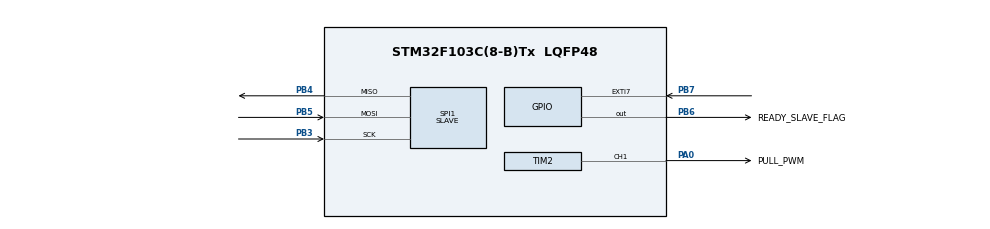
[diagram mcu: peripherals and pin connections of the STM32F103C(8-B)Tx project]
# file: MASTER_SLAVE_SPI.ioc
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Dma.Request0=SPI1_TX
Dma.Request1=SPI1_RX
Dma.SPI1_RX.1.Direction=DMA_PERIPH_TO_MEMORY
Dma.SPI1_RX.1.Instance=DMA1_Channel2
Dma.SPI1_RX.1.MemDataAlignment=DMA_MDATAALIGN_BYTE
Dma.SPI1_RX.1.MemInc=DMA_MINC_ENABLE
Dma.SPI1_RX.1.Mode=DMA_NORMAL
Dma.SPI1_RX.1.PeriphDataAlignment=DMA_PDATAALIGN_BYTE
Dma.SPI1_RX.1.PeriphInc=DMA_PINC_DISABLE
Dma.SPI1_RX.1.Priority=DMA_PRIORITY_LOW
Dma.SPI1_TX.0.Direction=DMA_MEMORY_TO_PERIPH
Dma.SPI1_TX.0.Instance=DMA1_Channel3
Dma.SPI1_TX.0.MemDataAlignment=DMA_MDATAALIGN_BYTE
Dma.SPI1_TX.0.MemInc=DMA_MINC_ENABLE
Dma.SPI1_TX.0.Mode=DMA_NORMAL
Dma.SPI1_TX.0.PeriphDataAlignment=DMA_PDATAALIGN_BYTE
Dma.SPI1_TX.0.PeriphInc=DMA_PINC_DISABLE
Dma.SPI1_TX.0.Priority=DMA_PRIORITY_LOW
Mcu.Family=STM32F1
Mcu.Name=STM32F103C(8-B)Tx
Mcu.Package=LQFP48
NVIC.DMA1_Channel2_IRQn=true\:0\:0\:false\:false\:true\:false\:true\:true
NVIC.DMA1_Channel3_IRQn=true\:0\:0\:false\:false\:true\:false\:true\:true
NVIC.EXTI9_5_IRQn=true\:0\:0\:false\:false\:true\:true\:true\:true
NVIC.PriorityGroup=NVIC_PRIORITYGROUP_4
NVIC.SPI1_IRQn=true\:0\:0\:false\:false\:true\:true\:true\:true
NVIC.TIM1_BRK_IRQn=true\:0\:0\:false\:false\:true\:true\:true\:true
NVIC.TIM1_UP_IRQn=true\:0\:0\:false\:false\:true\:true\:true\:true
PA0-WKUP.GPIO_Label=PULL_PWM
PA0-WKUP.GPIO_ModeDefaultPP=GPIO_MODE_AF_OD
PA0-WKUP.Signal=S_TIM2_CH1_ETR
PB3.Mode=Full_Duplex_Slave
PB3.Signal=SPI1_SCK
PB4.Mode=Full_Duplex_Slave
PB4.Signal=SPI1_MISO
PB5.Mode=Full_Duplex_Slave
PB5.Signal=SPI1_MOSI
PB6.GPIO_Label=READY_SLAVE_FLAG
PB6.Signal=GPIO_Output
PB7.GPIO_ModeDefaultEXTI=GPIO_MODE_IT_FALLING
PB7.Signal=GPXTI7
PD0-OSC_IN.Mode=HSE-External-Oscillator
PD0-OSC_IN.Signal=RCC_OSC_IN
PD1-OSC_OUT.Mode=HSE-External-Oscillator
PD1-OSC_OUT.Signal=RCC_OSC_OUT
ProjectManager.HeapSize=0x200
ProjectManager.StackSize=0x400
ProjectManager.TargetToolchain=STM32CubeIDE
RCC.AHBFreq_Value=8000000
RCC.APB1Freq_Value=8000000
RCC.APB1TimFreq_Value=8000000
RCC.APB2Freq_Value=8000000
RCC.APB2TimFreq_Value=8000000
RCC.HCLKFreq_Value=8000000
SH.S_TIM2_CH1_ETR.0=TIM2_CH1,PWM Generation1 CH1
SPI1.CRCCalculation=SPI_CRCCALCULATION_DISABLE
SPI1.Direction=SPI_DIRECTION_2LINES
SPI1.Mode=SPI_MODE_SLAVE
SPI1.VirtualType=VM_SLAVE
TIM1.Period=49999
TIM1.Prescaler=31
TIM2.AutoReloadPreload=TIM_AUTORELOAD_PRELOAD_ENABLE
TIM2.Channel-PWM\ Generation1\ CH1=TIM_CHANNEL_1
VP_CRC_VS_CRC.Mode=CRC_Activate
VP_SYS_VS_ND.Mode=No_Debug
VP_TIM1_VS_ClockSourceINT.Mode=Internal
VP_TIM1_VS_OPM.Mode=OPM_bit
VP_TIM2_VS_ClockSourceINT.Mode=Internal
board=custom

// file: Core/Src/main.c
/* USER CODE BEGIN Header */
/**
  ******************************************************************************
  * @file           : main.c
  * @brief          : Main program body
  ******************************************************************************
  * @attention
  *
  * Copyright (c) 2025 STMicroelectronics.
  * All rights reserved.
  *
  * This software is licensed under terms that can be found in the LICENSE file
  * in the root directory of this software component.
  * If no LICENSE file comes with this software, it is provided AS-IS.
  *
  ******************************************************************************
  */
/* USER CODE END Header */
#include "main.h"

/* USER CODE BEGIN Includes */

//#include "SPI_functions.h"
#include <stdio.h>
#include <string.h>
#include "protocol/spi_slave_protocol.h"
#include "spi_slave_registers.h"
/* USER CODE END Includes */

CRC_HandleTypeDef hcrc;

SPI_HandleTypeDef hspi1;
DMA_HandleTypeDef hdma_spi1_tx;
DMA_HandleTypeDef hdma_spi1_rx;

TIM_HandleTypeDef htim1;
TIM_HandleTypeDef htim2;

//Small
void SystemClock_Config(void);
static void MX_GPIO_Init(void);
static void MX_DMA_Init(void);
static void MX_SPI1_Init(void);
static void MX_TIM2_Init(void);
static void MX_TIM1_Init(void);
static void MX_CRC_Init(void);

int main(void)
{

  /* MCU Configuration--------------------------------------------------------*/

  /* Reset of all peripherals, Initializes the Flash interface and the Systick. */
  HAL_Init();

  /* Configure the system clock */
  SystemClock_Config();

  /* Initialize all configured peripherals */
  MX_GPIO_Init();
  MX_DMA_Init();
  MX_SPI1_Init();
  MX_TIM2_Init();
  MX_TIM1_Init();
  MX_CRC_Init();
  /* USER CODE BEGIN 2 */
  HAL_GPIO_WritePin(READY_SLAVE_FLAG_GPIO_Port, READY_SLAVE_FLAG_Pin,GPIO_PIN_RESET);
  /* USER CODE END 2 */

  /* Infinite loop */
  /* USER CODE BEGIN WHILE */
  while (1)
  {
	  monitor_register_changes();
    /* USER CODE END WHILE */

  }
}

void SystemClock_Config(void)
{
  RCC_OscInitTypeDef RCC_OscInitStruct = {0};
  RCC_ClkInitTypeDef RCC_ClkInitStruct = {0};

  /** Initializes the RCC Oscillators according to the specified parameters
  * in the RCC_OscInitTypeDef structure.
  */
  RCC_OscInitStruct.OscillatorType = RCC_OSCILLATORTYPE_HSI;
  RCC_OscInitStruct.HSIState = RCC_HSI_ON;
  RCC_OscInitStruct.HSICalibrationValue = RCC_HSICALIBRATION_DEFAULT;
  RCC_OscInitStruct.PLL.PLLState = RCC_PLL_NONE;
  if (HAL_RCC_OscConfig(&RCC_OscInitStruct) != HAL_OK)
  {
    Error_Handler();
  }

  /** Initializes the CPU, AHB and APB buses clocks
  */
  RCC_ClkInitStruct.ClockType = RCC_CLOCKTYPE_HCLK|RCC_CLOCKTYPE_SYSCLK
                              |RCC_CLOCKTYPE_PCLK1|RCC_CLOCKTYPE_PCLK2;
  RCC_ClkInitStruct.SYSCLKSource = RCC_SYSCLKSOURCE_HSI;
  RCC_ClkInitStruct.AHBCLKDivider = RCC_SYSCLK_DIV1;
  RCC_ClkInitStruct.APB1CLKDivider = RCC_HCLK_DIV1;
  RCC_ClkInitStruct.APB2CLKDivider = RCC_HCLK_DIV1;

  if (HAL_RCC_ClockConfig(&RCC_ClkInitStruct, FLASH_LATENCY_0) != HAL_OK)
  {
    Error_Handler();
  }
}

static void MX_CRC_Init(void)
{

  hcrc.Instance = CRC;
  if (HAL_CRC_Init(&hcrc) != HAL_OK)
  {
    Error_Handler();
  }

}

static void MX_SPI1_Init(void)
{

  /* SPI1 parameter configuration*/
  hspi1.Instance = SPI1;
  hspi1.Init.Mode = SPI_MODE_SLAVE;
  hspi1.Init.Direction = SPI_DIRECTION_2LINES;
  hspi1.Init.DataSize = SPI_DATASIZE_8BIT;
  hspi1.Init.CLKPolarity = SPI_POLARITY_LOW;
  hspi1.Init.CLKPhase = SPI_PHASE_1EDGE;
  hspi1.Init.NSS = SPI_NSS_SOFT;
  hspi1.Init.FirstBit = SPI_FIRSTBIT_MSB;
  hspi1.Init.TIMode = SPI_TIMODE_DISABLE;
  hspi1.Init.CRCCalculation = SPI_CRCCALCULATION_DISABLE;
  hspi1.Init.CRCPolynomial = 10;
  if (HAL_SPI_Init(&hspi1) != HAL_OK)
  {
    Error_Handler();
  }

}

static void MX_TIM1_Init(void)
{

  TIM_ClockConfigTypeDef sClockSourceConfig = {0};
  TIM_MasterConfigTypeDef sMasterConfig = {0};

  htim1.Instance = TIM1;
  htim1.Init.Prescaler = 31;
  htim1.Init.CounterMode = TIM_COUNTERMODE_UP;
  htim1.Init.Period = 49999;
  htim1.Init.ClockDivision = TIM_CLOCKDIVISION_DIV1;
  htim1.Init.RepetitionCounter = 0;
  htim1.Init.AutoReloadPreload = TIM_AUTORELOAD_PRELOAD_DISABLE;
  if (HAL_TIM_Base_Init(&htim1) != HAL_OK)
  {
    Error_Handler();
  }
  sClockSourceConfig.ClockSource = TIM_CLOCKSOURCE_INTERNAL;
  if (HAL_TIM_ConfigClockSource(&htim1, &sClockSourceConfig) != HAL_OK)
  {
    Error_Handler();
  }
  if (HAL_TIM_OnePulse_Init(&htim1, TIM_OPMODE_SINGLE) != HAL_OK)
  {
    Error_Handler();
  }
  sMasterConfig.MasterOutputTrigger = TIM_TRGO_RESET;
  sMasterConfig.MasterSlaveMode = TIM_MASTERSLAVEMODE_DISABLE;
  if (HAL_TIMEx_MasterConfigSynchronization(&htim1, &sMasterConfig) != HAL_OK)
  {
    Error_Handler();
  }

}

static void MX_TIM2_Init(void)
{

  TIM_ClockConfigTypeDef sClockSourceConfig = {0};
  TIM_MasterConfigTypeDef sMasterConfig = {0};
  TIM_OC_InitTypeDef sConfigOC = {0};

  htim2.Instance = TIM2;
  htim2.Init.Prescaler = 0;
  htim2.Init.CounterMode = TIM_COUNTERMODE_UP;
  htim2.Init.Period = 65535;
  htim2.Init.ClockDivision = TIM_CLOCKDIVISION_DIV1;
  htim2.Init.AutoReloadPreload = TIM_AUTORELOAD_PRELOAD_ENABLE;
  if (HAL_TIM_Base_Init(&htim2) != HAL_OK)
  {
    Error_Handler();
  }
  sClockSourceConfig.ClockSource = TIM_CLOCKSOURCE_INTERNAL;
  if (HAL_TIM_ConfigClockSource(&htim2, &sClockSourceConfig) != HAL_OK)
  {
    Error_Handler();
  }
  if (HAL_TIM_PWM_Init(&htim2) != HAL_OK)
  {
    Error_Handler();
  }
  sMasterConfig.MasterOutputTrigger = TIM_TRGO_RESET;
  sMasterConfig.MasterSlaveMode = TIM_MASTERSLAVEMODE_DISABLE;
  if (HAL_TIMEx_MasterConfigSynchronization(&htim2, &sMasterConfig) != HAL_OK)
  {
    Error_Handler();
  }
  sConfigOC.OCMode = TIM_OCMODE_PWM1;
  sConfigOC.Pulse = 0;
  sConfigOC.OCPolarity = TIM_OCPOLARITY_HIGH;
  sConfigOC.OCFastMode = TIM_OCFAST_DISABLE;
  if (HAL_TIM_PWM_ConfigChannel(&htim2, &sConfigOC, TIM_CHANNEL_1) != HAL_OK)
  {
    Error_Handler();
  }
  HAL_TIM_MspPostInit(&htim2);

}

static void MX_DMA_Init(void)
{

  /* DMA controller clock enable */
  __HAL_RCC_DMA1_CLK_ENABLE();

  /* DMA interrupt init */
  /* DMA1_Channel2_IRQn interrupt configuration */
  HAL_NVIC_SetPriority(DMA1_Channel2_IRQn, 0, 0);
  HAL_NVIC_EnableIRQ(DMA1_Channel2_IRQn);
  /* DMA1_Channel3_IRQn interrupt configuration */
  HAL_NVIC_SetPriority(DMA1_Channel3_IRQn, 0, 0);
  HAL_NVIC_EnableIRQ(DMA1_Channel3_IRQn);

}

static void MX_GPIO_Init(void)
{
  GPIO_InitTypeDef GPIO_InitStruct = {0};

  /* GPIO Ports Clock Enable */
  __HAL_RCC_GPIOD_CLK_ENABLE();
  __HAL_RCC_GPIOA_CLK_ENABLE();
  __HAL_RCC_GPIOB_CLK_ENABLE();

  /*Configure GPIO pin Output Level */
  HAL_GPIO_WritePin(READY_SLAVE_FLAG_GPIO_Port, READY_SLAVE_FLAG_Pin, GPIO_PIN_RESET);

  /*Configure GPIO pin : READY_SLAVE_FLAG_Pin */
  GPIO_InitStruct.Pin = READY_SLAVE_FLAG_Pin;
  GPIO_InitStruct.Mode = GPIO_MODE_OUTPUT_PP;
  GPIO_InitStruct.Pull = GPIO_NOPULL;
  GPIO_InitStruct.Speed = GPIO_SPEED_FREQ_LOW;
  HAL_GPIO_Init(READY_SLAVE_FLAG_GPIO_Port, &GPIO_InitStruct);

  /*Configure GPIO pin : PB7 */
  GPIO_InitStruct.Pin = GPIO_PIN_7;
  GPIO_InitStruct.Mode = GPIO_MODE_IT_FALLING;
  GPIO_InitStruct.Pull = GPIO_NOPULL;
  HAL_GPIO_Init(GPIOB, &GPIO_InitStruct);

  /* EXTI interrupt init*/
  HAL_NVIC_SetPriority(EXTI9_5_IRQn, 0, 0);
  HAL_NVIC_EnableIRQ(EXTI9_5_IRQn);

}

void Error_Handler(void)
{
  __disable_irq();
  while (1)
  {
  }
}
